AUTOSAR XML (schema 4-2-2)
package /Components
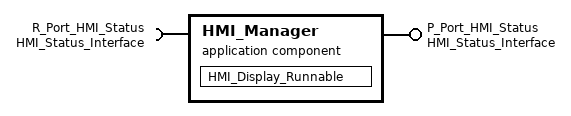
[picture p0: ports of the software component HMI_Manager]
  application sw component type HMI_Manager
    provide port P_Port_HMI_Status: provided-interface=HMI_Status_Interface
    require port R_Port_HMI_Status: required-interface=HMI_Status_Interface
    behavior HMI_Manager_BHV
      data received event StatusUpdate: start-on-event=HMI_Display_Runnable
      runnable HMI_Display_Runnable: symbol=HMI_Update_Symbol
        data-receive-point-by-arguments:
          access SystemStatus
          access StatusDetails
